# iostr912fa register map
Registers are 32-bit, access not given, no defined reset value unless marked. A register's access mark holds for its fields unless they carry their own. Addresses are absolute; registers are grouped by the start of their names; [hi:lo] are bit positions; 'fields as' and 'values as' point back to an identical list.

## CAN
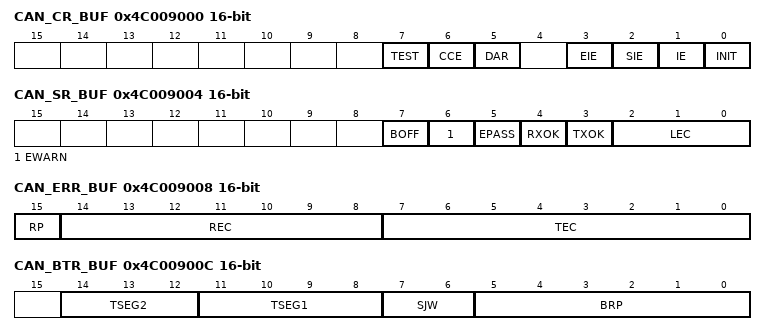
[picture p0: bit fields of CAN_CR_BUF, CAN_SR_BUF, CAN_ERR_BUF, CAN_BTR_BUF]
0x4C009000 CAN_CR_BUF 16-bit
  [7] TEST, [6] CCE, [5] DAR, [3] EIE, [2] SIE, [1] IE, [0] INIT
0x4C009004 CAN_SR_BUF 16-bit
  [7] BOFF, [6] EWARN, [5] EPASS, [4] RXOK, [3] TXOK, [2:0] LEC
0x4C009008 CAN_ERR_BUF 16-bit
  [15] RP, [14:8] REC, [7:0] TEC
0x4C00900C CAN_BTR_BUF 16-bit
  [14:12] TSEG2, [11:8] TSEG1, [7:6] SJW, [5:0] BRP
0x4C009010 CAN_IDR_BUF 16-bit
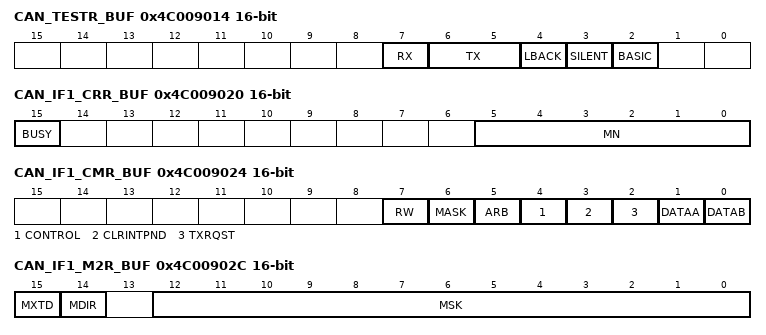
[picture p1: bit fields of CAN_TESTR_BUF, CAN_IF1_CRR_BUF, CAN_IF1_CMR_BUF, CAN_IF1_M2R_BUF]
0x4C009014 CAN_TESTR_BUF 16-bit
  [7] RX, [6:5] TX, [4] LBACK, [3] SILENT, [2] BASIC
0x4C009018 CAN_BRPR_BUF 16-bit
  [3:0] BRPE
0x4C009020 CAN_IF1_CRR_BUF 16-bit
  [15] BUSY, [5:0] MN
0x4C009024 CAN_IF1_CMR_BUF 16-bit
  [7] RW, [6] MASK, [5] ARB, [4] CONTROL, [3] CLRINTPND, [2] TXRQST, [1] DATAA, [0] DATAB
0x4C009028 CAN_IF1_M1R_BUF 16-bit
0x4C00902C CAN_IF1_M2R_BUF 16-bit
  [15] MXTD, [14] MDIR, [12:0] MSK
0x4C009030 CAN_IF1_A1R_BUF 16-bit
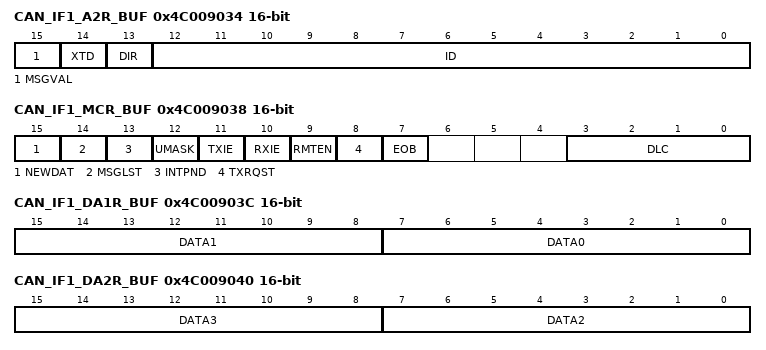
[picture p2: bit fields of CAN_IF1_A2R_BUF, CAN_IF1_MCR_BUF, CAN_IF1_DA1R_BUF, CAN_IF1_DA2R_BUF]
0x4C009034 CAN_IF1_A2R_BUF 16-bit
  [15] MSGVAL, [14] XTD, [13] DIR, [12:0] ID
0x4C009038 CAN_IF1_MCR_BUF 16-bit
  [15] NEWDAT, [14] MSGLST, [13] INTPND, [12] UMASK, [11] TXIE, [10] RXIE, [9] RMTEN, [8] TXRQST, [7] EOB, [3:0] DLC
0x4C00903C CAN_IF1_DA1R_BUF 16-bit
  [15:8] DATA1, [7:0] DATA0
0x4C009040 CAN_IF1_DA2R_BUF 16-bit
  [15:8] DATA3, [7:0] DATA2
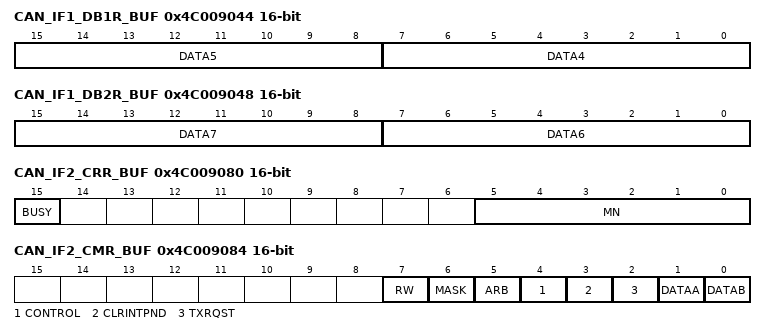
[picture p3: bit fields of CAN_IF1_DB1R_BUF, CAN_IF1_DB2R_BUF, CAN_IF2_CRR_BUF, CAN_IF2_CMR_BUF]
0x4C009044 CAN_IF1_DB1R_BUF 16-bit
  [15:8] DATA5, [7:0] DATA4
0x4C009048 CAN_IF1_DB2R_BUF 16-bit
  [15:8] DATA7, [7:0] DATA6
0x4C009080 CAN_IF2_CRR_BUF 16-bit
  [15] BUSY, [5:0] MN
0x4C009084 CAN_IF2_CMR_BUF 16-bit
  fields as CAN_IF1_CMR_BUF
0x4C009088 CAN_IF2_M1R_BUF 16-bit
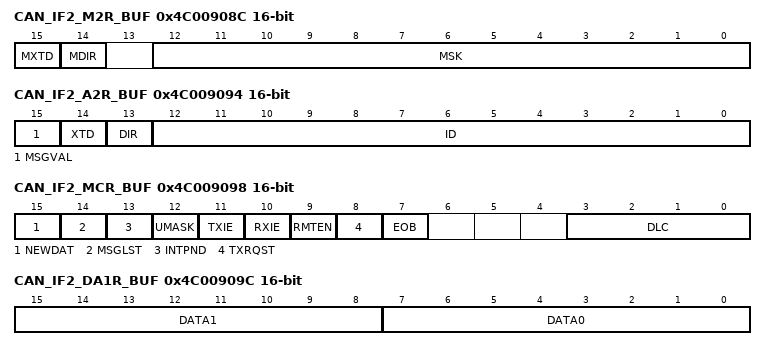
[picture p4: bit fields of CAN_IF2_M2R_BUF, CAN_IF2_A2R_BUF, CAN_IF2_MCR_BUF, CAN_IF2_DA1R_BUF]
0x4C00908C CAN_IF2_M2R_BUF 16-bit
  [15] MXTD, [14] MDIR, [12:0] MSK
0x4C009090 CAN_IF2_A1R_BUF 16-bit
0x4C009094 CAN_IF2_A2R_BUF 16-bit
  [15] MSGVAL, [14] XTD, [13] DIR, [12:0] ID
0x4C009098 CAN_IF2_MCR_BUF 16-bit
  fields as CAN_IF1_MCR_BUF
0x4C00909C CAN_IF2_DA1R_BUF 16-bit
  [15:8] DATA1, [7:0] DATA0
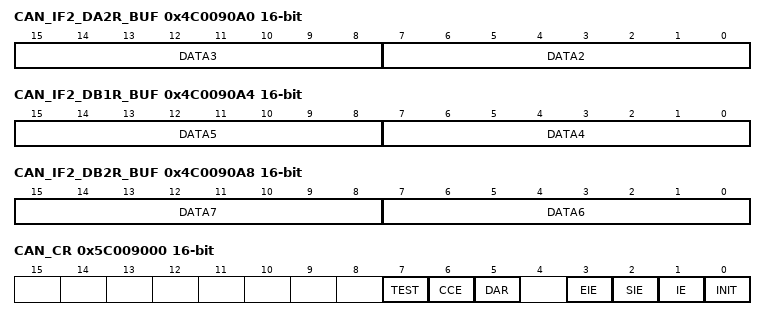
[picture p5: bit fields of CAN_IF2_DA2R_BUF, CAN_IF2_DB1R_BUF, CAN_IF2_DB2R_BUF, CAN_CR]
0x4C0090A0 CAN_IF2_DA2R_BUF 16-bit
  [15:8] DATA3, [7:0] DATA2
0x4C0090A4 CAN_IF2_DB1R_BUF 16-bit
  [15:8] DATA5, [7:0] DATA4
0x4C0090A8 CAN_IF2_DB2R_BUF 16-bit
  [15:8] DATA7, [7:0] DATA6
0x4C009100 CAN_TxR1R_BUF
0x4C009104 CAN_TxR2R_BUF
0x4C009120 CAN_ND1R_BUF
0x4C009124 CAN_ND2R_BUF
0x4C009140 CAN_IP1R_BUF
0x4C009144 CAN_IP2R_BUF
0x4C009160 CAN_MV1R_BUF
0x4C009164 CAN_MV2R_BUF
0x5C009000 CAN_CR 16-bit
  [7] TEST, [6] CCE, [5] DAR, [3] EIE, [2] SIE, [1] IE, [0] INIT
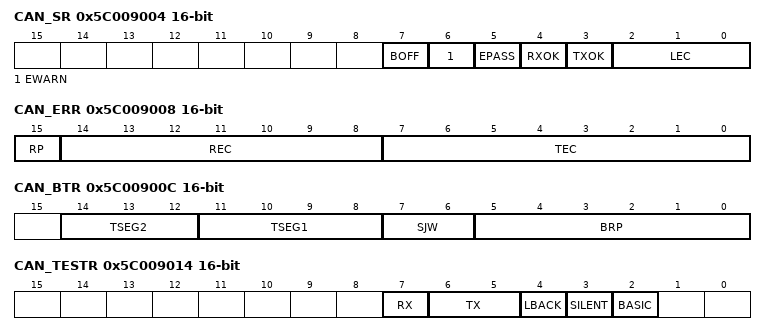
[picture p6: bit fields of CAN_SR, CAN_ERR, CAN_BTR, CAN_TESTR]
0x5C009004 CAN_SR 16-bit
  [7] BOFF, [6] EWARN, [5] EPASS, [4] RXOK, [3] TXOK, [2:0] LEC
0x5C009008 CAN_ERR 16-bit
  [15] RP, [14:8] REC, [7:0] TEC
0x5C00900C CAN_BTR 16-bit
  [14:12] TSEG2, [11:8] TSEG1, [7:6] SJW, [5:0] BRP
0x5C009010 CAN_IDR 16-bit
0x5C009014 CAN_TESTR 16-bit
  [7] RX, [6:5] TX, [4] LBACK, [3] SILENT, [2] BASIC
0x5C009018 CAN_BRPR 16-bit
  [3:0] BRPE
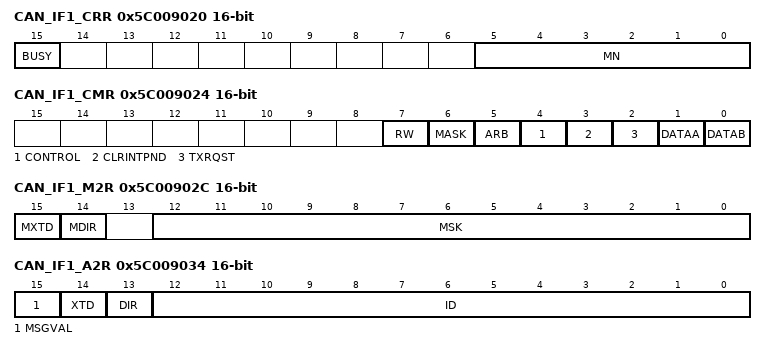
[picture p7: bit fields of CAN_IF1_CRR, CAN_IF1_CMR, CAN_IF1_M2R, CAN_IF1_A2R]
0x5C009020 CAN_IF1_CRR 16-bit
  [15] BUSY, [5:0] MN
0x5C009024 CAN_IF1_CMR 16-bit
  fields as CAN_IF1_CMR_BUF
0x5C009028 CAN_IF1_M1R 16-bit
0x5C00902C CAN_IF1_M2R 16-bit
  [15] MXTD, [14] MDIR, [12:0] MSK
0x5C009030 CAN_IF1_A1R 16-bit
0x5C009034 CAN_IF1_A2R 16-bit
  [15] MSGVAL, [14] XTD, [13] DIR, [12:0] ID
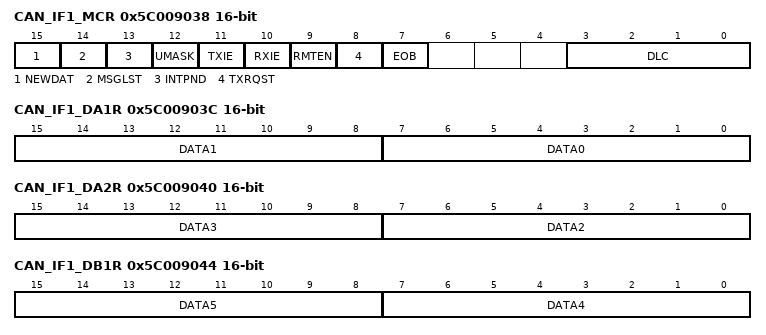
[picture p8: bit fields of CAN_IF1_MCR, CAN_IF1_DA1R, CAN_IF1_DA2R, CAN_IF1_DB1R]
0x5C009038 CAN_IF1_MCR 16-bit
  fields as CAN_IF1_MCR_BUF
0x5C00903C CAN_IF1_DA1R 16-bit
  [15:8] DATA1, [7:0] DATA0
0x5C009040 CAN_IF1_DA2R 16-bit
  [15:8] DATA3, [7:0] DATA2
0x5C009044 CAN_IF1_DB1R 16-bit
  [15:8] DATA5, [7:0] DATA4
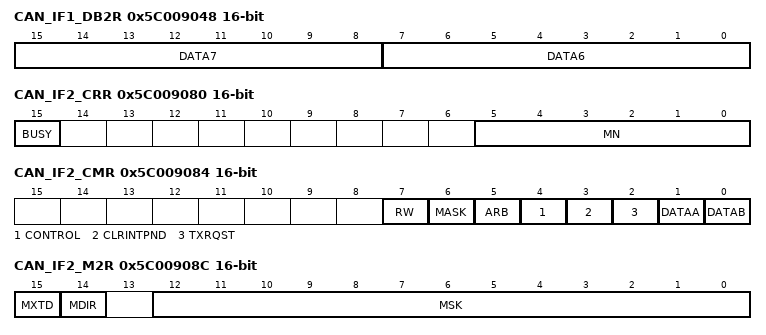
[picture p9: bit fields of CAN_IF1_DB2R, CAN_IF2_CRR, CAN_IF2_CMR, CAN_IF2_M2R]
0x5C009048 CAN_IF1_DB2R 16-bit
  [15:8] DATA7, [7:0] DATA6
0x5C009080 CAN_IF2_CRR 16-bit
  [15] BUSY, [5:0] MN
0x5C009084 CAN_IF2_CMR 16-bit
  fields as CAN_IF1_CMR_BUF
0x5C009088 CAN_IF2_M1R 16-bit
0x5C00908C CAN_IF2_M2R 16-bit
  [15] MXTD, [14] MDIR, [12:0] MSK
0x5C009090 CAN_IF2_A1R 16-bit
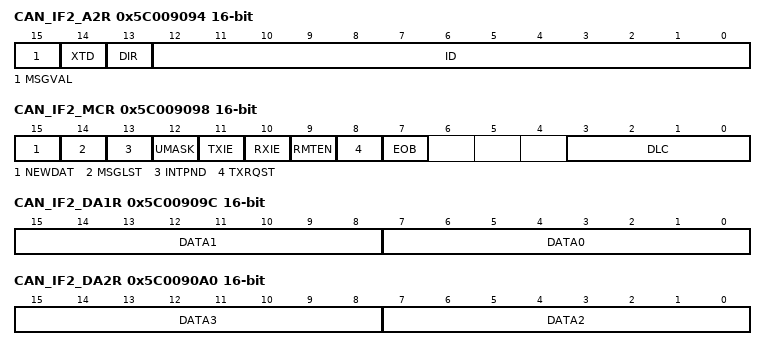
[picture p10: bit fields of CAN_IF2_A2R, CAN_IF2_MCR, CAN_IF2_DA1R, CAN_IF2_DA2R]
0x5C009094 CAN_IF2_A2R 16-bit
  [15] MSGVAL, [14] XTD, [13] DIR, [12:0] ID
0x5C009098 CAN_IF2_MCR 16-bit
  fields as CAN_IF1_MCR_BUF
0x5C00909C CAN_IF2_DA1R 16-bit
  [15:8] DATA1, [7:0] DATA0
0x5C0090A0 CAN_IF2_DA2R 16-bit
  [15:8] DATA3, [7:0] DATA2
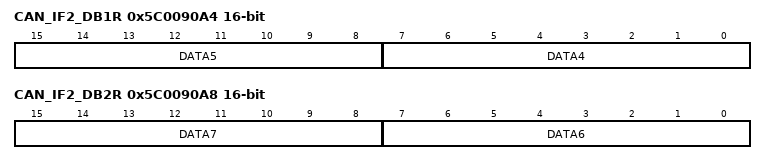
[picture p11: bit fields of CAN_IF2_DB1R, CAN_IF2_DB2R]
0x5C0090A4 CAN_IF2_DB1R 16-bit
  [15:8] DATA5, [7:0] DATA4
0x5C0090A8 CAN_IF2_DB2R 16-bit
  [15:8] DATA7, [7:0] DATA6
0x5C009100 CAN_TxR1R
0x5C009104 CAN_TxR2R
0x5C009120 CAN_ND1R
0x5C009124 CAN_ND2R
0x5C009140 CAN_IP1R
0x5C009144 CAN_IP2R
0x5C009160 CAN_MV1R
0x5C009164 CAN_MV2R
